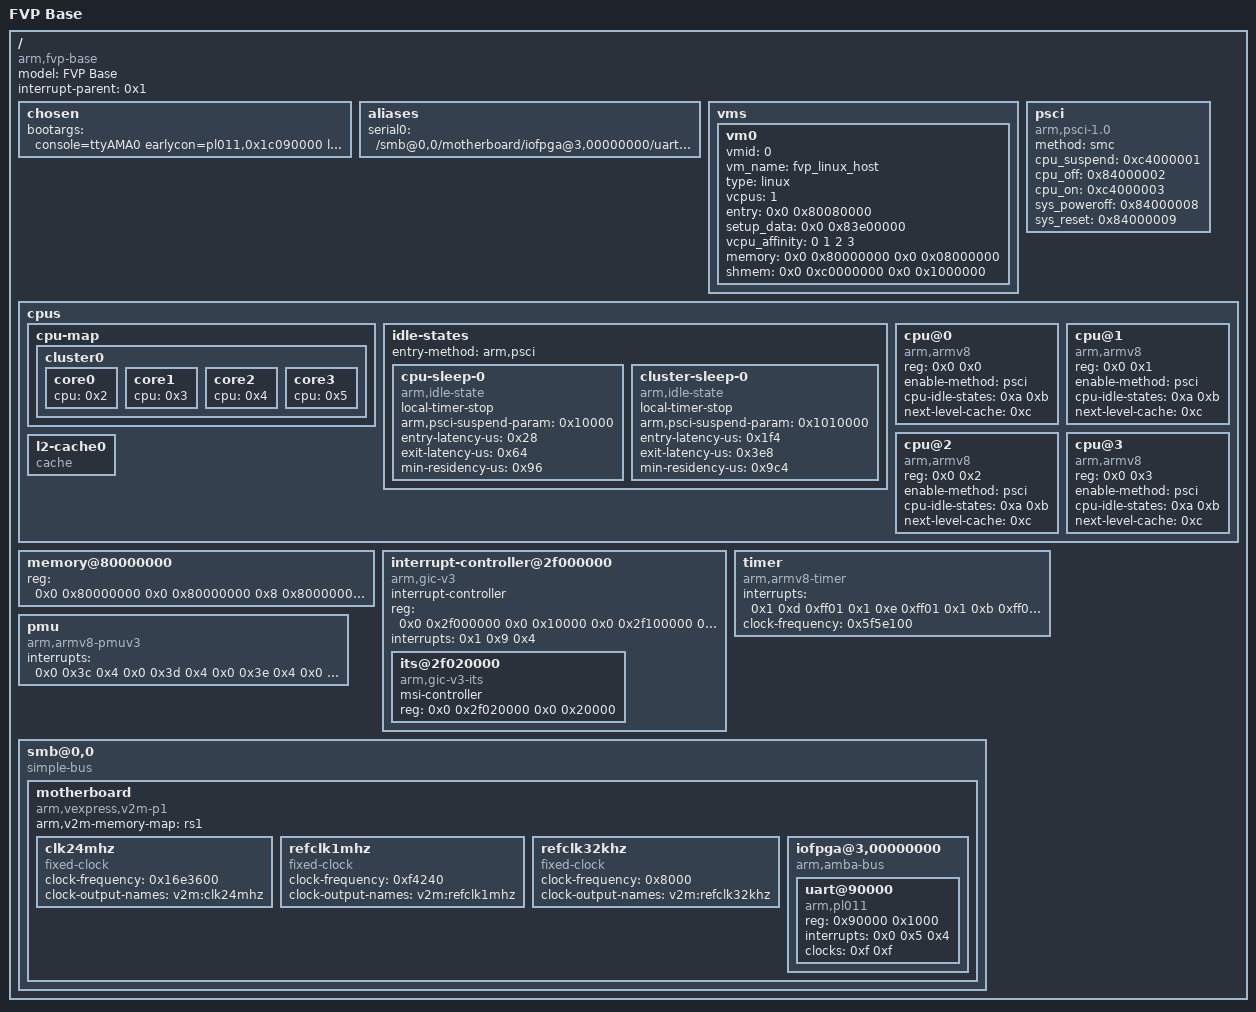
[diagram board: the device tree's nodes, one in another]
/dts-v1/;

/ {
	model = "FVP Base";
	compatible = "arm,fvp-base", "arm,vexpress";
	interrupt-parent = <0x1>;
	#address-cells = <0x2>;
	#size-cells = <0x2>;

	chosen {
		bootargs = "console=ttyAMA0 earlycon=pl011,0x1c090000 loglevel=8 consolelog=9 root=/dev/vda2 rw";
	};

	aliases {
		serial0 = "/smb@0,0/motherboard/iofpga@3,00000000/uart@90000";
	};

	vms {
		vm0 {
			device_type = "virtual_machine";
			vmid = <0>;
			vm_name = "fvp_linux_host";
			type = "linux";
			vcpus = <1>;
			entry = <0x0 0x80080000>;
			setup_data = <0x0 0x83e00000>;
			vcpu_affinity = <0 1 2 3>;
			memory = <0x0 0x80000000 0x0 0x08000000>;
			shmem = <0x0 0xc0000000 0x0 0x1000000>;
		};
/*
		vm1 {
			device_type = "virtual_machine";
			vmid = <1>;
			vm_name = "fvp_linux_vm1";
			type = "linux";
			vcpus = "2";
			entry = <0x0 0x90080000>;
			setup_data = <0x0 0x97e00000>;
			vcpu_affinity = <1 2>;
			memory = <0x0 0x90000000 0x0 0x08000000>;;
			shmem = <0x0 0xc0000000 0x0 0x10000000>;
		};

		vm_mailboxs {

		}
*/
	};

	psci {
		compatible = "arm,psci-1.0", "arm,psci-0.2", "arm,psci";
		method = "smc";
		cpu_suspend = <0xc4000001>;
		cpu_off = <0x84000002>;
		cpu_on = <0xc4000003>;
		sys_poweroff = <0x84000008>;
		sys_reset = <0x84000009>;
	};

	cpus {
		#address-cells = <0x2>;
		#size-cells = <0x0>;

		cpu-map {

			cluster0 {

				core0 {
					cpu = <0x2>;
				};

				core1 {
					cpu = <0x3>;
				};

				core2 {
					cpu = <0x4>;
				};

				core3 {
					cpu = <0x5>;
				};
			};
		};

		idle-states {
			entry-method = "arm,psci";

			cpu-sleep-0 {
				compatible = "arm,idle-state";
				local-timer-stop;
				arm,psci-suspend-param = <0x10000>;
				entry-latency-us = <0x28>;
				exit-latency-us = <0x64>;
				min-residency-us = <0x96>;
				linux,phandle = <0xa>;
				phandle = <0xa>;
			};

			cluster-sleep-0 {
				compatible = "arm,idle-state";
				local-timer-stop;
				arm,psci-suspend-param = <0x1010000>;
				entry-latency-us = <0x1f4>;
				exit-latency-us = <0x3e8>;
				min-residency-us = <0x9c4>;
				linux,phandle = <0xb>;
				phandle = <0xb>;
			};
		};

		cpu@0 {
			device_type = "cpu";
			compatible = "arm,armv8";
			reg = <0x0 0x0>;
			enable-method = "psci";
			cpu-idle-states = <0xa 0xb>;
			next-level-cache = <0xc>;
			linux,phandle = <0x2>;
			phandle = <0x2>;
		};

		cpu@1 {
			device_type = "cpu";
			compatible = "arm,armv8";
			reg = <0x0 0x1>;
			enable-method = "psci";
			cpu-idle-states = <0xa 0xb>;
			next-level-cache = <0xc>;
			linux,phandle = <0x3>;
			phandle = <0x3>;
		};

		cpu@2 {
			device_type = "cpu";
			compatible = "arm,armv8";
			reg = <0x0 0x2>;
			enable-method = "psci";
			cpu-idle-states = <0xa 0xb>;
			next-level-cache = <0xc>;
			linux,phandle = <0x4>;
			phandle = <0x4>;
		};

		cpu@3 {
			device_type = "cpu";
			compatible = "arm,armv8";
			reg = <0x0 0x3>;
			enable-method = "psci";
			cpu-idle-states = <0xa 0xb>;
			next-level-cache = <0xc>;
			linux,phandle = <0x5>;
			phandle = <0x5>;
		};

		l2-cache0 {
			compatible = "cache";
			linux,phandle = <0xc>;
			phandle = <0xc>;
		};
	};

	memory@80000000 {
		device_type = "memory";
		reg = <0x0 0x80000000 0x0 0x80000000 0x8 0x80000000 0x0 0x80000000>;
	};

	interrupt-controller@2f000000 {
		compatible = "arm,gic-v3";
		#interrupt-cells = <0x3>;
		#address-cells = <0x2>;
		#size-cells = <0x2>;
		ranges;
		interrupt-controller;
		reg = <0x0 0x2f000000 0x0 0x10000 0x0 0x2f100000 0x0 0x200000 0x0 0x2c000000 0x0 0x2000 0x0 0x2c010000 0x0 0x2000 0x0 0x2c02f000 0x0 0x2000>;
		interrupts = <0x1 0x9 0x4>;
		linux,phandle = <0x1>;
		phandle = <0x1>;

		its@2f020000 {
			compatible = "arm,gic-v3-its";
			msi-controller;
			reg = <0x0 0x2f020000 0x0 0x20000>;
		};
	};

	timer {
		compatible = "arm,armv8-timer";
		interrupts = <0x1 0xd 0xff01 0x1 0xe 0xff01 0x1 0xb 0xff01 0x1 0xa 0xff01>;
		clock-frequency = <0x5f5e100>;
	};

	pmu {
		compatible = "arm,armv8-pmuv3";
		interrupts = <0x0 0x3c 0x4 0x0 0x3d 0x4 0x0 0x3e 0x4 0x0 0x3f 0x4>;
	};

	smb@0,0 {
		compatible = "simple-bus";
		#address-cells = <0x2>;
		#size-cells = <0x1>;
		ranges = <0x0 0x0 0x0 0x8000000 0x4000000 0x1 0x0 0x0 0x14000000 0x4000000 0x2 0x0 0x0 0x18000000 0x4000000 0x3 0x0 0x0 0x1c000000 0x4000000 0x4 0x0 0x0 0xc000000 0x4000000 0x5 0x0 0x0 0x10000000 0x4000000>;

		motherboard {
			arm,v2m-memory-map = "rs1";
			compatible = "arm,vexpress,v2m-p1", "simple-bus";
			#address-cells = <0x2>;
			#size-cells = <0x1>;
			ranges;

			clk24mhz {
				compatible = "fixed-clock";
				#clock-cells = <0x0>;
				clock-frequency = <0x16e3600>;
				clock-output-names = "v2m:clk24mhz";
				linux,phandle = <0xf>;
				phandle = <0xf>;
			};

			refclk1mhz {
				compatible = "fixed-clock";
				#clock-cells = <0x0>;
				clock-frequency = <0xf4240>;
				clock-output-names = "v2m:refclk1mhz";
				linux,phandle = <0xe>;
				phandle = <0xe>;
			};

			refclk32khz {
				compatible = "fixed-clock";
				#clock-cells = <0x0>;
				clock-frequency = <0x8000>;
				clock-output-names = "v2m:refclk32khz";
				linux,phandle = <0xd>;
				phandle = <0xd>;
			};

			iofpga@3,00000000 {
				compatible = "arm,amba-bus", "simple-bus";
				#address-cells = <0x1>;
				#size-cells = <0x1>;
				ranges = <0x0 0x3 0x0 0x200000>;

				uart@90000 {
					compatible = "arm,pl011", "arm,primecell";
					reg = <0x90000 0x1000>;
					interrupts = <0x0 0x5 0x4>;
					clocks = <0xf 0xf>;
					clock-names = "uartclk", "apb_pclk";
				};
			};
		};
	};
};
